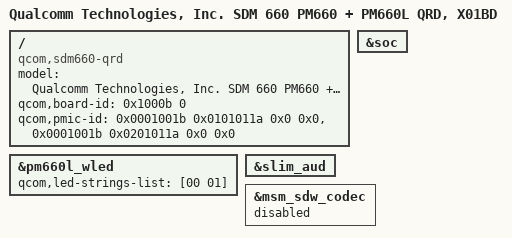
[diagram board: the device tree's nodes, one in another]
/* Copyright (c) 2018-2019, The Linux Foundation. All rights reserved.
 * 
 * This program is free software; you can redistribute it and/or modify
 * it under the terms of the GNU General Public License version 2 and
 * only version 2 as published by the Free Software Foundation.
 *
 * This program is distributed in the hope that it will be useful,
 * but WITHOUT ANY WARRANTY; without even the implied warranty of
 * MERCHANTABILITY or FITNESS FOR A PARTICULAR PURPOSE.  See the
 * GNU General Public License for more details.
 */

/dts-v1/;

#include "sdm660.dtsi"
#include "X01BD/X01BD-sdm660.dtsi"
#include "X01BD/X01BD-sdm660-mdss-panel.dtsi"
#include "sdm660-qrd.dtsi"
#include "X01BD/X01BD-sdm660-pinctrl.dtsi"
#include "X01BD/X01BD-sdm660-camera.dtsi"
#include "X01BD/X01BD-sdm660-qrd-common.dtsi"
#include "sdm660-internal-codec.dtsi"

/ {
	model = "Qualcomm Technologies, Inc. SDM 660 PM660 + PM660L QRD, X01BD";
	compatible = "qcom,sdm660-qrd", "qcom,sdm660", "qcom,qrd";
	qcom,board-id = <0x1000b 0>;
	qcom,pmic-id = <0x0001001b 0x0101011a 0x0 0x0>,
			<0x0001001b 0x0201011a 0x0 0x0>;
};

&pm660l_wled {
	qcom,led-strings-list = [00 01];
};

&slim_aud {
	/delete-node/wcd934x_cdc;
};

&soc {
	/delete-node/sound-tavil;
};

&msm_sdw_codec {
	status = "disabled";
};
